# renode register map
Vendor: litex
Litex SoC 2021-05-01 18:46:16
Registers are 32-bit, read-write, reset 0x0 unless marked. A register's access mark holds for its fields unless they carry their own. Offsets are from the block's base; lines under a group give offsets from that group; [hi:lo] are bit positions; {n}, {i} and the like mark numbered series; 'fields as' and 'values as' point back to an identical list; <NAME> marks a mode.

## Memory map
0xF0000000 REBOOT size 0xC
0xF0001000 CRG size 0x20
0xF0002000 GPIO size 0x24
0xF0004000 UART size 0x20
0xF0006000 CONSOLE size 0x20
0xF0008000 APP_UART size 0x20
0xF0009000 INFO size 0x30
0xF000A000 SRAM_EXT size 0x8
0xF000B000 MEMLCD size 0x18
0xF000C000 COM size 0x1C
0xF000D000 I2C size 0x24
0xF000E000 BTEVENTS size 0xC
0xF000F000 MESSIBLE size 0xC
0xF0010000 MESSIBLE2 size 0xC
0xF0011000 TICKTIMER size 0x20
0xF0012000 SUSRES size 0x30
0xF0013000 POWER size 0x14
0xF0014000 SPINOR size 0x34
0xF0015000 KEYBOARD size 0x38
0xF0016000 KEYINJECT size 0x4
0xF0017000 SEED size 0x8
0xF0018000 KEYROM size 0x8
0xF0019000 AUDIO size 0x24
0xF001A000 TRNG_KERNEL size 0x14
0xF001B000 TRNG_SERVER size 0x24
0xF001C000 TRNG size 0x50
0xF001D000 SHA512 size 0x60
0xF001E000 ENGINE size 0x24
0xF001F000 JTAG size 0x8
0xF0020000 WDT size 0x1C
0xF0021000 D11CTIME size 0x8
0xF0022000 IDENTIFIER_MEM size 0x4
0xF0023000 TIMER0 size 0x20

## Interrupts
0 timer0 (TIMER0)
1 gpio (GPIO)
2 uart (UART)
3 console (CONSOLE)
4 app_uart (APP_UART)
5 com (COM)
6 i2c (I2C)
7 btevents (BTEVENTS)
8 ticktimer (TICKTIMER)
9 susres (SUSRES)
10 power (POWER)
11 keyboard (KEYBOARD)
12 audio (AUDIO)
13 trng_kernel (TRNG_KERNEL)
14 trng_server (TRNG_SERVER)
15 sha512 (SHA512)
16 engine (ENGINE)
17 wdt (WDT)

## Further device data
memoryRegions:
  ROM baseAddress=0x00000000 size=0x00008000
  SRAM baseAddress=0x10000000 size=0x00020000
  VEXRISCV_DEBUG baseAddress=0xEFFF0000 size=0x00000100
  SRAM_EXT baseAddress=0x40000000 size=0x01000000
  MEMLCD baseAddress=0xB0000000 size=0x00005C20
  SPIFLASH baseAddress=0x20000000 size=0x08000000
  AUDIO baseAddress=0xE0000000 size=0x00000004
  SHA512 baseAddress=0xE0002000 size=0x00000008
  ENGINE baseAddress=0xE0020000 size=0x00020000
  CSR baseAddress=0xF0000000 size=0x00040000
constants:
  CONFIG_CLOCK_FREQUENCY value=100000000
  CONFIG_CPU_HAS_INTERRUPT value=None
  CONFIG_CPU_RESET_ADDR value=0
  CONFIG_CPU_TYPE_VEXRISCV value=None
  CONFIG_CPU_VARIANT_STANDARD value=None
  CONFIG_CPU_HUMAN_NAME value=VexRiscv
  CONFIG_CPU_NOP value=nop
  CONFIG_CSR_DATA_WIDTH value=32
  CONFIG_CSR_ALIGNMENT value=32
  CONFIG_BUS_STANDARD value=WISHBONE
  CONFIG_BUS_DATA_WIDTH value=32
  CONFIG_BUS_ADDRESS_WIDTH value=32
  APP_UART_INTERRUPT value=4
  AUDIO_INTERRUPT value=12
  BTEVENTS_INTERRUPT value=7
  COM_INTERRUPT value=5
  CONSOLE_INTERRUPT value=3
  ENGINE_INTERRUPT value=16
  GPIO_INTERRUPT value=1
  I2C_INTERRUPT value=6
  KEYBOARD_INTERRUPT value=11
  POWER_INTERRUPT value=10
  SHA512_INTERRUPT value=15
  SUSRES_INTERRUPT value=9
  TICKTIMER_INTERRUPT value=8
  TIMER0_INTERRUPT value=0
  TRNG_KERNEL_INTERRUPT value=13
  TRNG_SERVER_INTERRUPT value=14
  UART_INTERRUPT value=2
  WDT_INTERRUPT value=17

## REBOOT
Base 0xF0000000
0x00 SOC_RESET — Writing 0xAC to this register will do a full SoC reset, including CRGs and peripherals
  [7:0] soc_reset
0x04 ADDR — The address written here will be used as the next reset vector
0x08 CPU_RESET — Writing anything to this register resets the CPU, and the CPU only; does not affect CRG or peripherals
  [0] cpu_reset

## CRG
Base 0xF0001000
0x00 MMCM_DRP_RESET
  [0] mmcm_drp_reset
0x04 MMCM_DRP_LOCKED
  [0] mmcm_drp_locked
0x08 MMCM_DRP_READ
  [0] mmcm_drp_read
0x0C MMCM_DRP_WRITE
  [0] mmcm_drp_write
0x10 MMCM_DRP_DRDY
  [0] mmcm_drp_drdy
0x14 MMCM_DRP_ADR
  [6:0] mmcm_drp_adr
0x18 MMCM_DRP_DAT_W
  [15:0] mmcm_drp_dat_w
0x1C MMCM_DRP_DAT_R
  [15:0] mmcm_drp_dat_r

## GPIO
Base 0xF0002000
0x00 OUTPUT — Values to appear on GPIO when respective `drive` bit is asserted
  [7:0] output
0x04 INPUT — Value measured on the respective GPIO pin
  [7:0] input
0x08 DRIVE — When a bit is set to `1`, the respective pad drives its value out
  [7:0] drive
0x0C INTENA — Enable interrupts when a respective bit is set
  [7:0] intena
0x10 INTPOL — When a bit is `1`, falling-edges cause interrupts. Otherwise, rising edges cause interrupts.
  [7:0] intpol
0x14 UARTSEL — Used to select which UART is routed to physical pins, 00 = kernel debug, 01 = console, others reserved based on build
  [1:0] uartsel
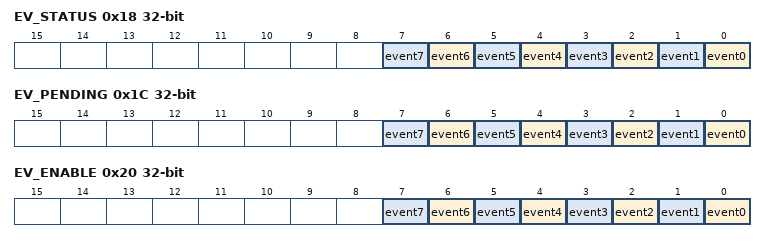
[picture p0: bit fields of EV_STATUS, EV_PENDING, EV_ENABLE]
0x18 EV_STATUS — This register contains the current raw level of the event7 event trigger. Writes to this register have no effect.
  [n] event{n} (n=0..7) — Level of the ``event{n}`` event
0x1C EV_PENDING — When a event7 event occurs, the corresponding bit will be set in this register. To clear the Event, set the corresponding bit in this register.
  [n] event{n} (n=0..7) — `1` if a this particular event occurred. This Event is triggered on a **rising** edge.
0x20 EV_ENABLE — This register enables the corresponding event7 events. Write a ``0`` to this register to disable individual events.
  [n] event{n} (n=0..7) — Write a ``1`` to enable the ``event{n}`` Event
